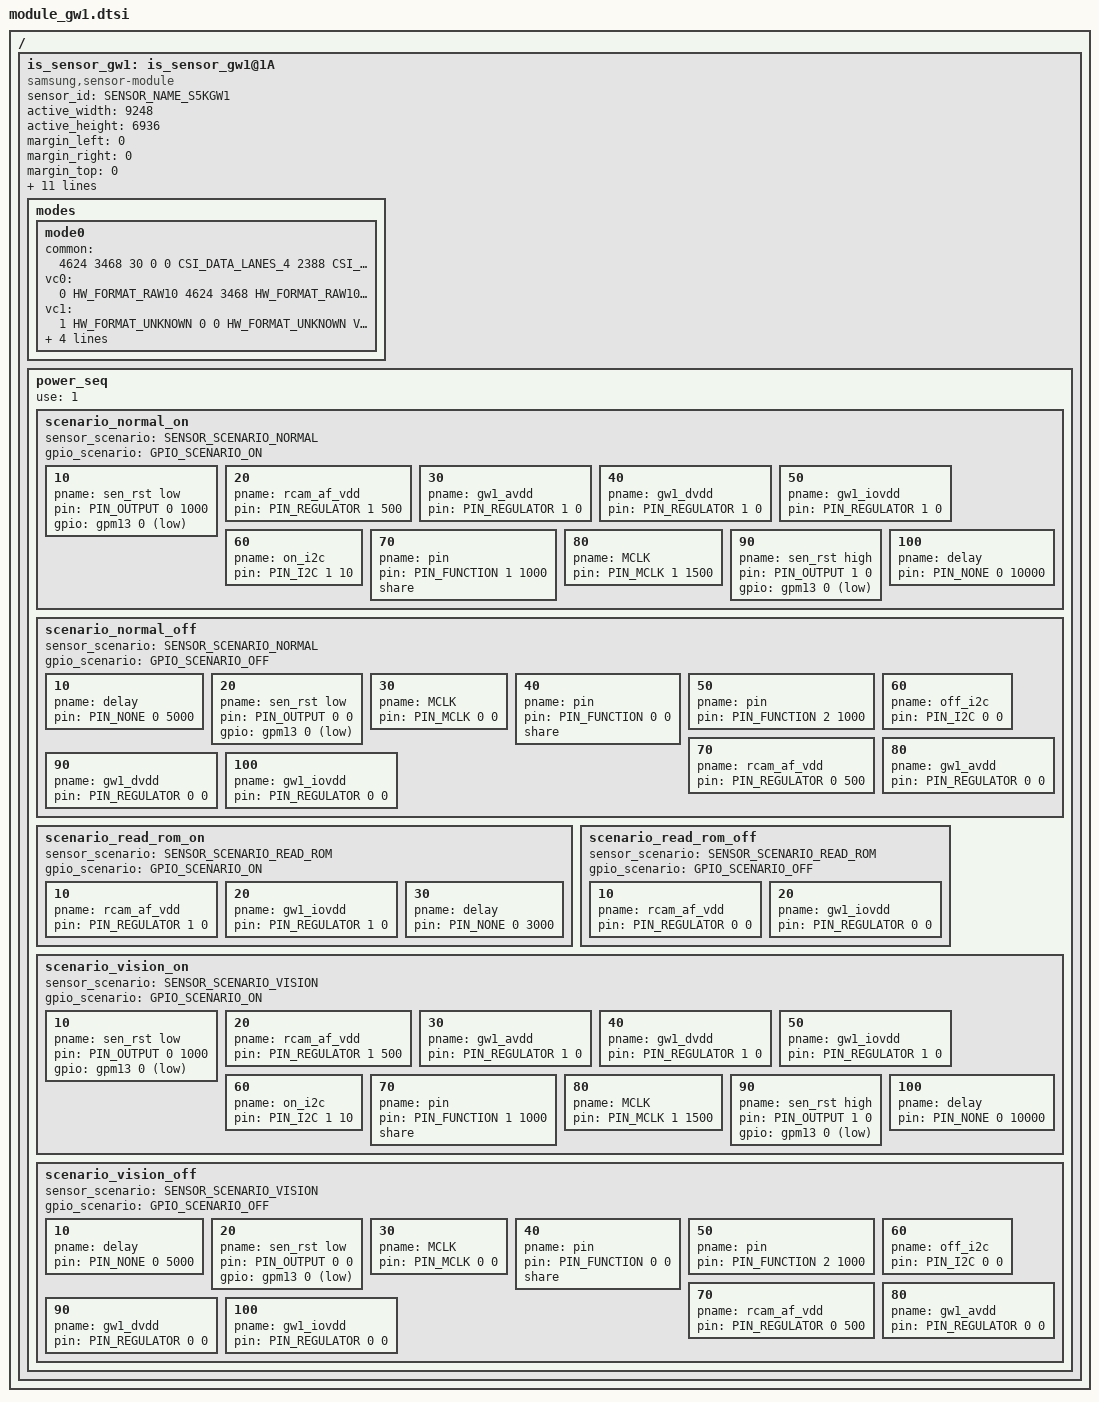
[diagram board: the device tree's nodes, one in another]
/*
 * SAMSUNG EXYNOSxxxx board camera device tree source
 *
 * Copyright (c) 2019 Samsung Electronics Co., Ltd.
 *		http://www.samsung.com
 *
 * This program is free software; you can redistribute it and/or modify
 * it under the terms of the GNU General Public License version 2 as
 * published by the Free Software Foundation.
 */

#include <dt-bindings/camera/exynos_is_dt.h>

#ifndef USE_VENDOR_PWR_PIN_NAME
#define RCAM_AF_VDD	<>     /* RCAM1_AFVDD_2P8 */
#define GW1_IOVDD	<>     /* CAM_VDDIO_1P8 : CAM0_VLDO3 is used for all camera commonly */
#define GW1_AVDD	<>     /* RCAM1_AVDD1_2P9 */
#define GW1_DVDD	<>     /* RCAM1_DVDD_1P1 */
#endif

/ {
	fragment@camera {
		target-path = "/";
		__overlay__ {
			is_sensor_gw1: is_sensor_gw1@1A {
				compatible = "samsung,sensor-module";

				/* common */
				sensor_id = <SENSOR_NAME_S5KGW1>;
				active_width = <9248>;
				active_height = <6936>;
				margin_left = <0>;
				margin_right = <0>;
				margin_top = <0>;
				margin_bottom = <0>;
				max_framerate = <240>;
				bitwidth = <10>;
				use_retention_mode = <SENSOR_RETENTION_INACTIVE>;
				sensor_maker = "SLSI";
				sensor_name = "S5KGW1";
				setfile_name = "setfile_gw1.bin";

				rcam_af_vdd-supply = RCAM_AF_VDD;
				gw1_iovdd-supply = GW1_IOVDD;
				gw1_avdd-supply = GW1_AVDD;
				gw1_dvdd-supply = GW1_DVDD;

				status = "okay";
#if 0
				vc_extra {
					/* ex) statX = <stat_type, sensor_mode, max_width, max_height, max_element> */
					stat0 = </* not avaliable */>;									/* VC_BUF_DATA_TYPE_SENSOR_STAT1 */
					stat1 = </*VC_STAT_TYPE_PAFSTAT_FLOATING*/ 300 /*VC_SENSOR_MODE_SUPER_PD_2_TAIL*/ 403 584 3468 2>;	/* VC_BUF_DATA_TYPE_GENERAL_STAT1 */
					stat2 = </* not avaliable */>;									/* VC_BUF_DATA_TYPE_SENSOR_STAT2 */
					stat3 = </*VC_STAT_TYPE_PAFSTAT_STATIC*/ 301    /*VC_SENSOR_MODE_SUPER_PD_2_TAIL*/ 403 584 3468 2>;	/* VC_BUF_DATA_TYPE_GENERAL_STAT2 */
				};
#endif

#if 0
				/* sensor modes */
				modes {
						/* common = <width, height, fps, settle, mode, lane, speed, interleave, lrte, pd_mode> */
						/* vcX = <map, hwformat, width, height, hwformat, type, width, height> */

					/* 2x2 BIN For Single Still Preview / Capture */
					mode0 {
						common = <4624 3468 30 0 0 CSI_DATA_LANES_4 2388 CSI_MODE_VC_ONLY LRTE_DISABLE PD_MSPD_TAIL EX_NONE>;
						vc0 = </* in */ 0 HW_FORMAT_RAW10 4624 3468	/* out */ HW_FORMAT_RAW10 VC_NOTHING 0 0>;
						vc1 = </* in */ 1 HW_FORMAT_RAW10 584   3468	/* out */ HW_FORMAT_UNKNOWN VC_NOTHING 0 0>;
						vc2 = </* in */ 2 HW_FORMAT_UNKNOWN 0 0		/* out */ HW_FORMAT_USER VC_MIPISTAT 584 3468>;
						vc3 = </* in */ 3 HW_FORMAT_UNKNOWN 0 0		/* out */ HW_FORMAT_USER VC_PRIVATE   584 3468>;
					};
				};
#else
				/* sensor modes */
				modes {
						/* common = <width, height, fps, settle, mode, lane, speed, interleave, lrte, pd_mode> */
						/* vcX = <map, hwformat, width, height, hwformat, type, width, height> */

					/* 2x2 BIN For Single Still Preview / Capture */
					mode0 {
						common = <4624 3468 30 0 0 CSI_DATA_LANES_4 2388 CSI_MODE_VC_ONLY LRTE_DISABLE PD_NONE EX_NONE>;
						vc0 = </* in */ 0 HW_FORMAT_RAW10 4624 3468	/* out */ HW_FORMAT_RAW10 VC_NOTHING 0 0>;
						vc1 = </* in */ 1 HW_FORMAT_UNKNOWN 0 0	      /* out */ HW_FORMAT_UNKNOWN VC_NOTHING 0 0>;
						vc2 = </* in */ 2 HW_FORMAT_UNKNOWN 0 0		/* out */ HW_FORMAT_UNKNOWN VC_NOTHING 0 0>;
						vc3 = </* in */ 3 HW_FORMAT_UNKNOWN 0 0		/* out */ HW_FORMAT_UNKNOWN VC_NOTHING 0 0>;
					};
				};
#endif

				power_seq {
					use = <1>;
					scenario_normal_on {
						sensor_scenario = <SENSOR_SCENARIO_NORMAL>;
						gpio_scenario = <GPIO_SCENARIO_ON>;

						/* A start node number should be over the 10 for reserved number 0~9. */
						/* pname = "name"; 			pin = <act value dealy voltage>;		gpio = <gpx# # 0x1>; */
						10 { pname = "sen_rst low";		pin = <PIN_OUTPUT 0 1000>;			gpio = <&gpm13 0 0x1>;	};
						20 { pname = "rcam_af_vdd";		pin = <PIN_REGULATOR 1 500>;						};	/* RCAM_AF_VDD 2.8V */
						30 { pname = "gw1_avdd";		pin = <PIN_REGULATOR 1 0>;						};	/* AVDD 2.8V */
						40 { pname = "gw1_dvdd";		pin = <PIN_REGULATOR 1 0>;						};	/* DVDD 1.05V */
						50 { pname = "gw1_iovdd";		pin = <PIN_REGULATOR 1 0>;						};	/* IOVDD 1.8V */
						60 { pname = "on_i2c";			pin = <PIN_I2C 1 10>;							};
						70 { pname = "pin";			pin = <PIN_FUNCTION 1 1000>;			share;			};
						80 { pname = "MCLK";			pin = <PIN_MCLK 1 1500>;						};
						90 { pname = "sen_rst high";		pin = <PIN_OUTPUT 1 0>;				gpio = <&gpm13 0 0x1>;	};
						100 { pname = "delay";			pin = <PIN_NONE 0 10000>;						};
					};

					scenario_normal_off {
						sensor_scenario = <SENSOR_SCENARIO_NORMAL>;
						gpio_scenario = <GPIO_SCENARIO_OFF>;

						/* A start node number should be over the 10 for reserved number 0~9. */
						/* pname = "name"; 			pin = <act value dealy voltage>; 		gpio = <gpx# # 0x1>; */
						10 { pname = "delay"; 			pin = <PIN_NONE 0 5000>; 						};
						20 { pname = "sen_rst low"; 		pin = <PIN_OUTPUT 0 0>; 			gpio = <&gpm13 0 0x1>;	};
						30 { pname = "MCLK"; 			pin = <PIN_MCLK 0 0>; 							};
						40 { pname = "pin"; 			pin = <PIN_FUNCTION 0 0>; 			share; 			};
						50 { pname = "pin"; 			pin = <PIN_FUNCTION 2 1000>; 						};
						60 { pname = "off_i2c"; 		pin = <PIN_I2C 0 0>;							};
						70 { pname = "rcam_af_vdd";	 	pin = <PIN_REGULATOR 0 500>; 						};	/* RCAM_AF_VDD 2.8V */
						80 { pname = "gw1_avdd"; 		pin = <PIN_REGULATOR 0 0>; 						};	/* AVDD 2.8V */
						90 { pname = "gw1_dvdd"; 		pin = <PIN_REGULATOR 0 0>; 						};	/* DVDD 1.05V */
						100 { pname = "gw1_iovdd"; 		pin = <PIN_REGULATOR 0 0>; 						};	/* IOVDD 1.8V */
					};

					scenario_read_rom_on {
						sensor_scenario = <SENSOR_SCENARIO_READ_ROM>;
						gpio_scenario = <GPIO_SCENARIO_ON>;

						/* A start node number should be over the 10 for reserved number 0~9. */
						/* pname = "name";			pin = <act value dealy voltage>;		gpio = <gpx# # 0x1>; */
						10 { pname = "rcam_af_vdd";		pin = <PIN_REGULATOR 1 0>;						};	/* RCAM_AF_VDD 2.8V */
						20 { pname = "gw1_iovdd";		pin = <PIN_REGULATOR 1 0>;						};	/* IOVDD 1.8V */
						30 { pname = "delay";			pin = <PIN_NONE 0 3000>;						};
					};

					scenario_read_rom_off {
						sensor_scenario = <SENSOR_SCENARIO_READ_ROM>;
						gpio_scenario = <GPIO_SCENARIO_OFF>;

						/* A start node number should be over the 10 for reserved number 0~9. */
						/* pname = "name"; 			pin = <act value dealy voltage>; 		gpio = <gpx# # 0x1>; */
						10 { pname = "rcam_af_vdd";		pin = <PIN_REGULATOR 0 0>;						};	/* RCAM_AF_VDD 2.8V */
						20 { pname = "gw1_iovdd";		pin = <PIN_REGULATOR 0 0>;						};	/* IOVDD 1.8V */
					};

					scenario_vision_on {
						sensor_scenario = <SENSOR_SCENARIO_VISION>;
						gpio_scenario = <GPIO_SCENARIO_ON>;

						/* A start node number should be over the 10 for reserved number 0~9. */
						/* pname = "name"; 			pin = <act value dealy voltage>;		gpio = <gpx# # 0x1>; */
						10 { pname = "sen_rst low";		pin = <PIN_OUTPUT 0 1000>;			gpio = <&gpm13 0 0x1>;	};
						20 { pname = "rcam_af_vdd";		pin = <PIN_REGULATOR 1 500>;						};	/* RCAM_AF_VDD 2.8V */
						30 { pname = "gw1_avdd";		pin = <PIN_REGULATOR 1 0>;						};	/* AVDD 2.8V */
						40 { pname = "gw1_dvdd";		pin = <PIN_REGULATOR 1 0>;						};	/* DVDD 1.05V */
						50 { pname = "gw1_iovdd";		pin = <PIN_REGULATOR 1 0>;						};	/* IOVDD 1.8V */
						60 { pname = "on_i2c";			pin = <PIN_I2C 1 10>;							};
						70 { pname = "pin";			pin = <PIN_FUNCTION 1 1000>;			share;			};
						80 { pname = "MCLK";			pin = <PIN_MCLK 1 1500>;						};
						90 { pname = "sen_rst high";		pin = <PIN_OUTPUT 1 0>;				gpio = <&gpm13 0 0x1>;	};
						100 { pname = "delay";			pin = <PIN_NONE 0 10000>;						};
					};

					scenario_vision_off {
						sensor_scenario = <SENSOR_SCENARIO_VISION>;
						gpio_scenario = <GPIO_SCENARIO_OFF>;

						/* A start node number should be over the 10 for reserved number 0~9. */
						/* pname = "name"; 			pin = <act value dealy voltage>;		gpio = <gpx# # 0x1>; */
						10 { pname = "delay"; 			pin = <PIN_NONE 0 5000>;						};
						20 { pname = "sen_rst low"; 		pin = <PIN_OUTPUT 0 0>;				gpio = <&gpm13 0 0x1>;	};
						30 { pname = "MCLK"; 			pin = <PIN_MCLK 0 0>;							};
						40 { pname = "pin"; 			pin = <PIN_FUNCTION 0 0>;			share;			};
						50 { pname = "pin"; 			pin = <PIN_FUNCTION 2 1000>;						};
						60 { pname = "off_i2c"; 		pin = <PIN_I2C 0 0>;							};
						70 { pname = "rcam_af_vdd"; 		pin = <PIN_REGULATOR 0 500>;						};	/* RCAM_AF_VDD 2.8V */
						80 { pname = "gw1_avdd"; 		pin = <PIN_REGULATOR 0 0>;						};	/* AVDD 2.8V */
						90 { pname = "gw1_dvdd"; 		pin = <PIN_REGULATOR 0 0>;						};	/* DVDD 1.05V */
						100 { pname = "gw1_iovdd"; 		pin = <PIN_REGULATOR 0 0>;						};	/* IOVDD 1.8V */
					};
				};
			};
		}; /* end of __overlay__ */
	}; /* end of fragment */
}; /* end of root */

